# A31T21x register map
Vendor: ABOV Semiconductor Co., Ltd.; Series: A31T21x; File version: 1.0
CPU: CM0PLUS r0p1, little endian, no MPU, no FPU, VTOR, 2 interrupt priority bits
Registers are 32-bit, read-write, reset 0x0 unless marked. A register's access mark holds for its fields unless they carry their own. Offsets are from the block's base; [hi:lo] are bit positions.

## I2C0
Base 0x40004800
Same registers: I2C1 0x40004900
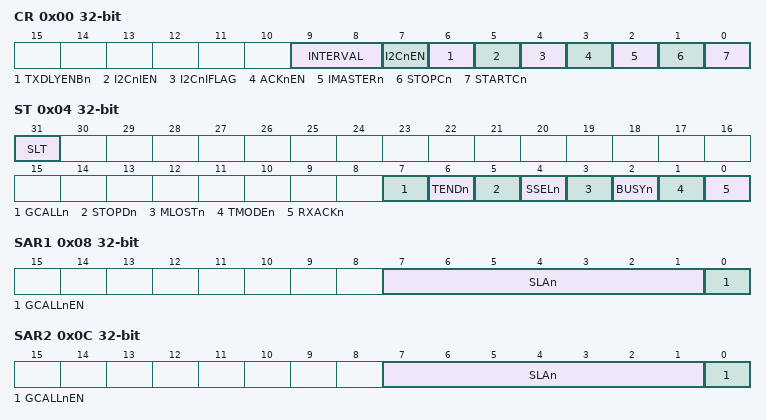
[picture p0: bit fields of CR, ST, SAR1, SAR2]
0x00 CR — I2Cn Control Register
  [9:8] INTERVAL — I2C bus internal delay between address and data transfer
  [7] I2CnEN — Activate I2Cn Block by supplying
  [6] TXDLYENBn — I2CnSDHR Register Control bit
  [5] I2CnIEN — I2Cn Interrupt Enable bit
  [4] I2CnIFLAG ro — I2Cn Interrupt Flag bit. This bit is cleared when write any values in the I2CnST register.
  [3] ACKnEN — Controls ACK signal generation at ninth SCL period. Notes) ACK signal is output (SDA = 0) for the following 3 cases. Where x = 0 and 1. 1. When received address packet equals to SLAx[6:0] bits in I2CnSARx register. 2. When received address packet equals to value 0x00 with GCALLn enabled. 3. When I2Cn operates as a receiver (master or slave)
  [2] IMASTERn ro — Represent Operation Mode of I2Cn
  [1] STOPCn — STOP Condition Generation When I2Cn is master.
  [0] STARTCn — START Condition Generation When I2Cn is master.
0x04 ST (reset mask 0xFF) — I2Cn Status Register
  [31] SLT — This bit shows SCL low timeout status
  [7] GCALLn — This bit has different meaning depending on whether I2C is master or slave. When I2C is a master, this bit represents whether it received AACK (address ACK) from slave.
  [6] TENDn — This bit is set when 1-byte of data is transferred completely.
  [5] STOPDn — This bit is set when a STOP condition is detected.
  [4] SSELn — This bit is set when I2C is addressed by other master.
  [3] MLOSTn — This bit represents the result of bus arbitration in master mode.
  [2] BUSYn — This bit reflects bus status.
  [1] TMODEn ro — This bit is used to indicate whether I2C is transmitter or receiver.
  [0] RXACKn — This bit shows the state of ACK signal.
0x08 SAR1 — I2Cn Slave Address Register 1
  [7:1] SLAn — These bits configure the slave address 0 in slave mode.
  [0] GCALLnEN — This bit decides whether I2Cn allows general call address 0 or not in I2Cn slave mode.
0x0C SAR2 — I2Cn Slave Address Register 2
  [7:1] SLAn — These bits configure the slave address 1 in slave mode.
  [0] GCALLnEN — This bit decides whether I2Cn allows general call address 1 or not in I2Cn slave mode.
0x10 DR — I2Cn Data Register
  [7:0] DATA — The I2CnDR Transmit buffer and Receive buffer share the same I/O address with this DATA register. The Transmit Data Buffer is the destination for data written to the I2CnDR register. Reading the I2CnDR register returns the contents of the Receive Buffer.
0x14 SDHR reset 0x1 — I2Cn SDA Hold Time Register
  [11:0] HLDT — This register is used to control SDA output timing from the falling edge of SCL. Note that SDA is changed after tPCLK X (I2CnSDHR+2). In master mode, load half the value of I2CnSCLR to this register to make SDA change in the middle of SCL. In slave mode, configure this register regarding the frequency of SCL from master. The SDA is changed after tPCLK X (I2CnSDHR+2) in master mode. So, to insure operation in slave mode, the value tPCLK X (I2CnSDHR + 2) must be smaller than the period of SCL.
0x18 SCLR reset 0x3F — I2Cn SCL Low Period Register
  [11:0] SCLL — This register defines the low period of SCL in master mode. The base clock is PCLK and the period is calculated by the formula: tPCLK X (4 X I2CnSCLR + 2) where tPCLK is the period of PCLK.
0x1C SCHR reset 0x3F — I2Cn SCL High Period Register
  [11:0] SCLH — This register defines the high period of SCL in master mode. The base clock is PCLK and the period is calculated by the formula: tPCLK X (4 X I2CnSCHR + 2) where tPCLK is the period of PCLK.
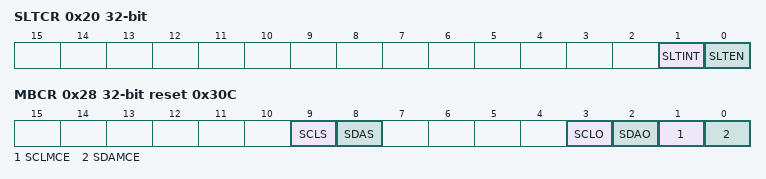
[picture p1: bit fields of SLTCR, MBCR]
0x20 SLTCR — I2Cn SCL low timeout control register
  [1] SLTINT — Selection of SCL low timeout interrupt
  [0] SLTEN — SCL low timeout enable bit
0x24 SLTPDR reset 0xFFFFFF (reset mask 0x0) — I2Cn SCL low timeout period data register
  [23:0] PDATA — This register defines the period of SCL low timeout
0x28 MBCR reset 0x30C (reset mask 0xCF3) — I2Cn manual bus control register
  [9] SCLS ro — SCL status bit
  [8] SDAS ro — SDA status bit
  [3] SCLO — SCL output data bit
  [2] SDAO — SDA output data bit
  [1] SCLMCE — SCL manual control enable bit
  [0] SDAMCE — SDA manual control enable bit

## Notices in the file
Copyright (C) 2012-2014 ARM Limited. All rights reserved.
Purpose: System Viewer Description (SVD) Example (Schema Version 1.1)
This is a description of a none-existent and incomplete device
for demonstration purposes only.
Redistribution and use in source and binary forms, with or without
modification, are permitted provided that the following conditions are met:
- Redistributions of source code must retain the above copyright
notice, this list of conditions and the following disclaimer.
- Redistributions in binary form must reproduce the above copyright
notice, this list of conditions and the following disclaimer in the
documentation and/or other materials provided with the distribution.
- Neither the name of ARM nor the names of its contributors may be used
to endorse or promote products derived from this software without
specific prior written permission.
THIS SOFTWARE IS PROVIDED BY THE COPYRIGHT HOLDERS AND CONTRIBUTORS "AS IS"
AND ANY EXPRESS OR IMPLIED WARRANTIES, INCLUDING, BUT NOT LIMITED TO, THE
IMPLIED WARRANTIES OF MERCHANTABILITY AND FITNESS FOR A PARTICULAR PURPOSE
ARE DISCLAIMED. IN NO EVENT SHALL COPYRIGHT HOLDERS AND CONTRIBUTORS BE
LIABLE FOR ANY DIRECT, INDIRECT, INCIDENTAL, SPECIAL, EXEMPLARY, OR
CONSEQUENTIAL DAMAGES (INCLUDING, BUT NOT LIMITED TO, PROCUREMENT OF
SUBSTITUTE GOODS OR SERVICES; LOSS OF USE, DATA, OR PROFITS; OR BUSINESS
INTERRUPTION) HOWEVER CAUSED AND ON ANY THEORY OF LIABILITY, WHETHER IN
CONTRACT, STRICT LIABILITY, OR TORT (INCLUDING NEGLIGENCE OR OTHERWISE)
ARISING IN ANY WAY OUT OF THE USE OF THIS SOFTWARE, EVEN IF ADVISED OF THE
POSSIBILITY OF SUCH DAMAGE.
